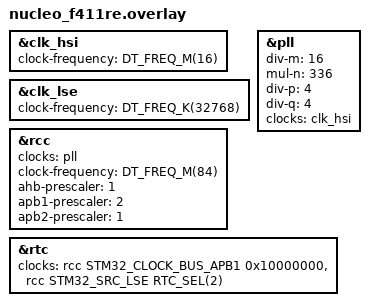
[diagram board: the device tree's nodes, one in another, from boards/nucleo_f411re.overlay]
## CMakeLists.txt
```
# SPDX-License-Identifier: Apache-2.0

cmake_minimum_required(VERSION 3.20.0)
set(ENV{BOARD} nucleo_f411re)
find_package(Zephyr REQUIRED HINTS $ENV{ZEPHYR_BASE})
project(Zephyr_RTC_STM32)

target_sources(app PRIVATE src/main.c)
```

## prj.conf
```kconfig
CONFIG_GPIO=y
CONFIG_COUNTER=y
CONFIG_HEAP_MEM_POOL_SIZE=256

CONFIG_COUNTER_RTC_STM32_SAVE_VALUE_BETWEEN_RESETS=y
CONFIG_COUNTER_RTC_STM32=y
CONFIG_COUNTER_RTC_STM32_CLOCK_LSE=y
CONFIG_COUNTER_RTC_STM32_CLOCK_LSI=n

CONFIG_POSIX_CLOCK=y
```

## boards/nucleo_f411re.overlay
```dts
    &clk_hsi {
        status = "okay";
        clock-frequency = < DT_FREQ_M(16) >;
    };
    &clk_lse {
        status = "okay";
        clock-frequency = < DT_FREQ_K(32768) >;
    };
    &pll {
        div-m = <16>;
        mul-n = <336>;
        div-p = <4>;
        div-q = <4>;
        clocks = <&clk_hsi>;
        status = "okay";
    };
    &rcc {
        clocks = <&pll>;
        clock-frequency = <DT_FREQ_M(84)>;
        ahb-prescaler = <1>;
        apb1-prescaler = <2>;
        apb2-prescaler = <1>;
    };
    &rtc {
        clocks = <&rcc STM32_CLOCK_BUS_APB1 0x10000000>,
             <&rcc STM32_SRC_LSE RTC_SEL(2)>;
        status = "okay";
    };
```

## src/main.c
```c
/*
 * Copyright (c) 2016 Intel Corporation
 *
 * SPDX-License-Identifier: Apache-2.0
 */

#include <zephyr/kernel.h>
#include <zephyr/device.h>
#include <zephyr/drivers/gpio.h>
#include <zephyr/sys/printk.h>
#include <zephyr/drivers/counter.h>
#include <string.h>
#include <zephyr/posix/time.h>
#define TIMER DT_INST(0, st_stm32_rtc)

/* 1000 msec = 1 sec */
#define SLEEP_TIME_MS   1000

/* The devicetree node identifier for the "led0" alias. */
#define LED0_NODE DT_ALIAS(led0)

static const struct gpio_dt_spec led = GPIO_DT_SPEC_GET(LED0_NODE, gpios);
const struct device *const counter_dev = DEVICE_DT_GET(TIMER);
time_t compile_timestamp = 1678984720;
struct timespec time_now_ts;

void main(void)
{
	int ret;

	if (!gpio_is_ready_dt(&led)) {
		return;
	}

	ret = gpio_pin_configure_dt(&led, GPIO_OUTPUT_ACTIVE);
	if (ret < 0) {
		return;
	}



    if (!device_is_ready(counter_dev)) {
        printk("device not ready.\n");
        return;
    };


    //if(counter_start(counter_dev)!=0) {
   //     printk("counter start failed.\n");
   //     return;
  //  };

    uint32_t *ticks = k_malloc(sizeof(uint32_t));
    memset(ticks, 0, sizeof(uint32_t));

	while (1) {
		ret = gpio_pin_toggle_dt(&led);
		if (ret < 0) {
			return;
		}

        int req = counter_get_value(counter_dev, ticks);

        if(req) {
            printk("counter get value failed.\n\r");
            return;
        }
        else{
            struct tm   ttm;

            time_t time_now = compile_timestamp + *ticks + 3600;
            ttm = * gmtime(&time_now);

            printk("counter value: %d\n\r", *ticks);
            printk("Current time: %02d:%02d:%02d\n\r", ttm.tm_hour, ttm.tm_min, ttm.tm_sec);
        }
		k_msleep(SLEEP_TIME_MS);
	}

}
```
